# CC3200 register map
Vendor: Texas Instruments; Series: SimpleLink; File version: 1.0
CPU: CM4 r0p1, little endian, MPU, no FPU, 3 interrupt priority bits
Registers are 32-bit, read-write, reset 0x0 unless marked. A register's access mark holds for its fields unless they carry their own. Offsets are from the block's base; [hi:lo] are bit positions; {n}, {i} and the like mark numbered series; 'fields as' and 'values as' point back to an identical list.

## TIMER — TIMERA0
Base 0x40030000
0x00 CFG — TIMER_CFG
  [2:0] M
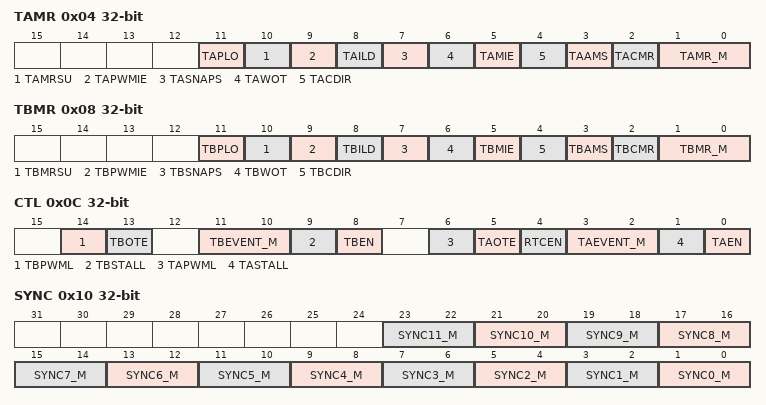
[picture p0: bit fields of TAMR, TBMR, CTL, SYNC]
0x04 TAMR — TIMER_TAMR
  [11] TAPLO — TIMER_TAMR
  [10] TAMRSU — TIMER_TAMR
  [9] TAPWMIE — TIMER_TAMR
  [8] TAILD — TIMER_TAMR
  [7] TASNAPS — TIMER_TAMR
  [6] TAWOT — TIMER_TAMR
  [5] TAMIE — TIMER_TAMR
  [4] TACDIR — TIMER_TAMR
  [3] TAAMS — TIMER_TAMR
  [2] TACMR — TIMER_TAMR
  [1:0] TAMR_M — TIMER_TAMR
0x08 TBMR — TIMER_TBMR
  [11] TBPLO — TIMER_TBMR
  [10] TBMRSU — TIMER_TBMR
  [9] TBPWMIE — TIMER_TBMR
  [8] TBILD — TIMER_TBMR
  [7] TBSNAPS — TIMER_TBMR
  [6] TBWOT — TIMER_TBMR
  [5] TBMIE — TIMER_TBMR
  [4] TBCDIR — TIMER_TBMR
  [3] TBAMS — TIMER_TBMR
  [2] TBCMR — TIMER_TBMR
  [1:0] TBMR_M — TIMER_TBMR
0x0C CTL — TIMER_CTL
  [14] TBPWML — TIMER_CTL
  [13] TBOTE — TIMER_CTL
  [11:10] TBEVENT_M — TIMER_CTL
  [9] TBSTALL — TIMER_CTL
  [8] TBEN — TIMER_CTL
  [6] TAPWML — TIMER_CTL
  [5] TAOTE — TIMER_CTL
  [4] RTCEN — TIMER_CTL
  [3:2] TAEVENT_M — TIMER_CTL
  [1] TASTALL — TIMER_CTL
  [0] TAEN — TIMER_CTL
0x10 SYNC — TIMER_SYNC
  [2n+1:2n] SYNC{n}_M (n=0..11) — TIMER_SYNC
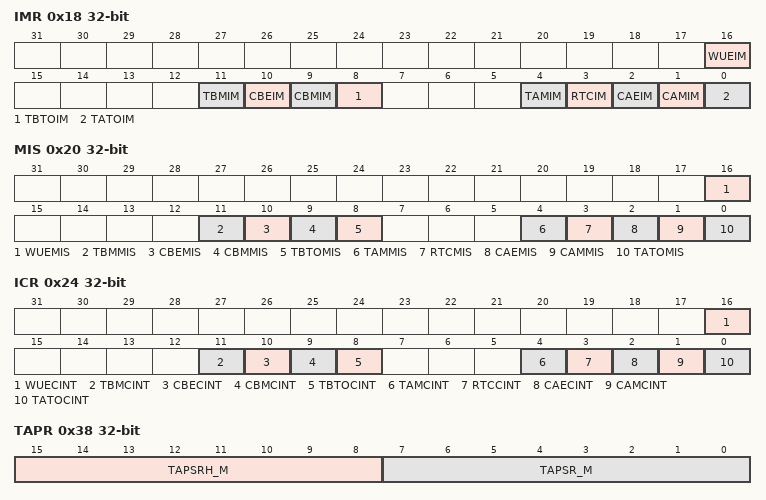
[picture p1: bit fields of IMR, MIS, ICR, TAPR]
0x18 IMR — TIMER_IMR
  [16] WUEIM — TIMER_IMR
  [11] TBMIM — TIMER_IMR
  [10] CBEIM — TIMER_IMR
  [9] CBMIM — TIMER_IMR
  [8] TBTOIM — TIMER_IMR
  [4] TAMIM — TIMER_IMR
  [3] RTCIM — TIMER_IMR
  [2] CAEIM — TIMER_IMR
  [1] CAMIM — TIMER_IMR
  [0] TATOIM — TIMER_IMR
0x1C RIS — TIMER_RIS
  [16] WUERIS — TIMER_RIS
  [11] TBMRIS — TIMER_RIS
  [10] CBEMIS — TIMER_RIS
  [10] CBERIS — TIMER_RIS
  [9] CBMMIS — TIMER_RIS
  [9] CBMRIS — TIMER_RIS
  [8] TBTOMIS — TIMER_RIS
  [8] TBTORIS — TIMER_RIS
  [4] TAMRIS — TIMER_RIS
  [3] RTCMIS — TIMER_RIS
  [3] RTCRIS — TIMER_RIS
  [2] CAEMIS — TIMER_RIS
  [2] CAERIS — TIMER_RIS
  [1] CAMMIS — TIMER_RIS
  [1] CAMRIS — TIMER_RIS
  [0] TATOMIS — TIMER_RIS
  [0] TATORIS — TIMER_RIS
0x20 MIS — TIMER_MIS
  [16] WUEMIS — TIMER_MIS
  [11] TBMMIS — TIMER_MIS
  [10] CBEMIS — TIMER_MIS
  [9] CBMMIS — TIMER_MIS
  [8] TBTOMIS — TIMER_MIS
  [4] TAMMIS — TIMER_MIS
  [3] RTCMIS — TIMER_MIS
  [2] CAEMIS — TIMER_MIS
  [1] CAMMIS — TIMER_MIS
  [0] TATOMIS — TIMER_MIS
0x24 ICR — TIMER_ICR
  [16] WUECINT — TIMER_ICR
  [11] TBMCINT — TIMER_ICR
  [10] CBECINT — TIMER_ICR
  [9] CBMCINT — TIMER_ICR
  [8] TBTOCINT — TIMER_ICR
  [4] TAMCINT — TIMER_ICR
  [3] RTCCINT — TIMER_ICR
  [2] CAECINT — TIMER_ICR
  [1] CAMCINT — TIMER_ICR
  [0] TATOCINT — TIMER_ICR
0x28 TAILR — TIMER_TAILR
  [31:0] M
0x2C TBILR — TIMER_TBILR
  [31:0] M
0x30 TAMATCHR — TIMER_TAMATCHR
  [31:16] TAMRH — TIMER_TAMATCHR
  [31:16] TAMRH_M — TIMER_TAMATCHR
  [31:0] TAMR_M — TIMER_TAMATCHR
  [15:0] TAMRL — TIMER_TAMATCHR
  [15:0] TAMRL_M — TIMER_TAMATCHR
0x34 TBMATCHR — TIMER_TBMATCHR
  [31:0] TBMR_M — TIMER_TBMATCHR
  [15:0] TBMRL — TIMER_TBMATCHR
  [15:0] TBMRL_M — TIMER_TBMATCHR
0x38 TAPR — TIMER_TAPR
  [15:8] TAPSRH_M — TIMER_TAPR
  [7:0] TAPSR_M — TIMER_TAPR
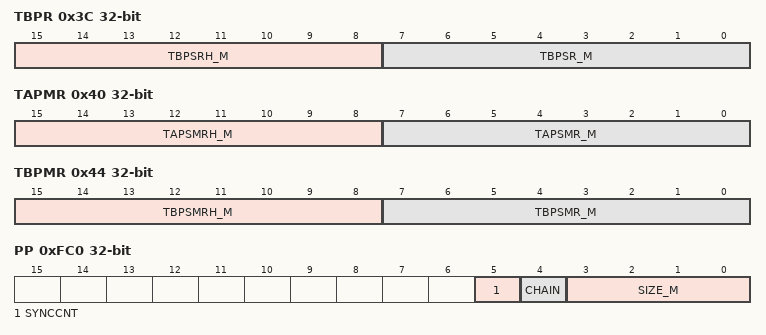
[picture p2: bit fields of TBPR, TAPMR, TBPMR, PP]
0x3C TBPR — TIMER_TBPR
  [15:8] TBPSRH_M — TIMER_TBPR
  [7:0] TBPSR_M — TIMER_TBPR
0x40 TAPMR — TIMER_TAPMR
  [15:8] TAPSMRH_M — TIMER_TAPMR
  [7:0] TAPSMR_M — TIMER_TAPMR
0x44 TBPMR — TIMER_TBPMR
  [15:8] TBPSMRH_M — TIMER_TBPMR
  [7:0] TBPSMR_M — TIMER_TBPMR
0x48 TAR — TIMER_TAR
  [31:0] M
0x4C TBR — TIMER_TBR
  [31:0] M
0x50 TAV — TIMER_TAV
  [31:0] M
0x54 TBV — TIMER_TBV
  [31:0] M
0x58 RTCPD — TIMER_RTCPD
  [15:0] RTCPD_M
0x5C TAPS — TIMER_TAPS
  [15:0] PSS_M
0x60 TBPS — TIMER_TBPS
  [15:0] PSS_M
0x64 TAPV — TIMER_TAPV
  [15:0] PSV_M
0x68 TBPV — TIMER_TBPV
  [15:0] PSV_M
0x6C DMAEV — TIMER_DMAEV
0xFC0 PP — TIMER_PP
  [5] SYNCCNT — TIMER_PP
  [4] CHAIN — TIMER_PP
  [3:0] SIZE_M — TIMER_PP

## TIMER — TIMERA1
Base 0x40031000
0x00 CFG — TIMER_CFG
  [2:0] M
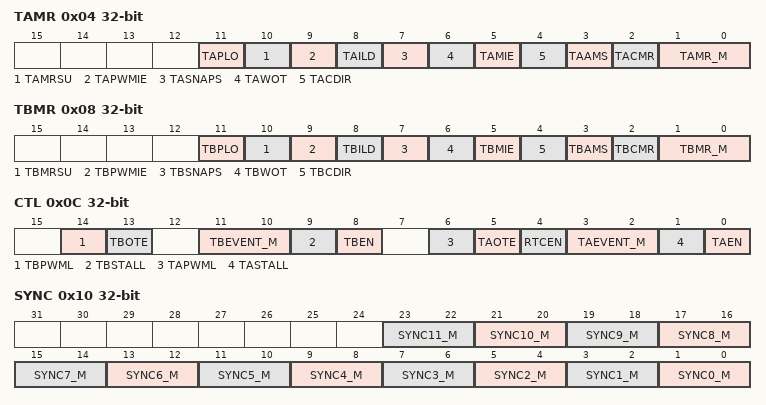
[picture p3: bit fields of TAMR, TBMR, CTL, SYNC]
0x04 TAMR — TIMER_TAMR
  fields as TAMR
0x08 TBMR — TIMER_TBMR
  fields as TBMR
0x0C CTL — TIMER_CTL
  fields as CTL
0x10 SYNC — TIMER_SYNC
  [2n+1:2n] SYNC{n}_M (n=0..11) — TIMER_SYNC
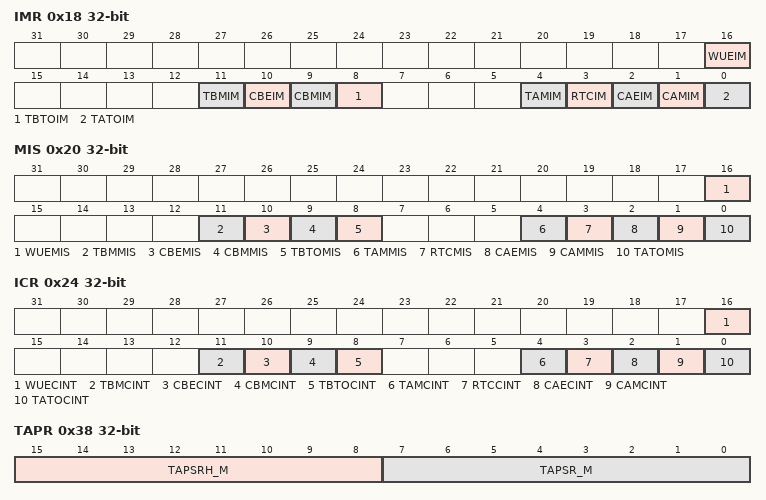
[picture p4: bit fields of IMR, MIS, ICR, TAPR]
0x18 IMR — TIMER_IMR
  fields as IMR
0x1C RIS — TIMER_RIS
  fields as RIS
0x20 MIS — TIMER_MIS
  fields as MIS
0x24 ICR — TIMER_ICR
  fields as ICR
0x28 TAILR — TIMER_TAILR
  [31:0] M
0x2C TBILR — TIMER_TBILR
  [31:0] M
0x30 TAMATCHR — TIMER_TAMATCHR
  fields as TAMATCHR
0x34 TBMATCHR — TIMER_TBMATCHR
  fields as TBMATCHR
0x38 TAPR — TIMER_TAPR
  [15:8] TAPSRH_M — TIMER_TAPR
  [7:0] TAPSR_M — TIMER_TAPR
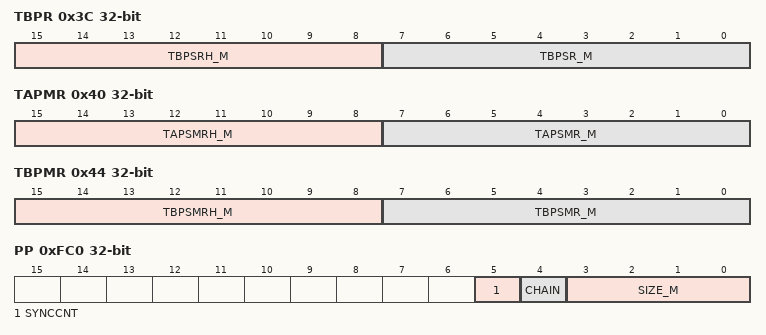
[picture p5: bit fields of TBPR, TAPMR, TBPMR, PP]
0x3C TBPR — TIMER_TBPR
  [15:8] TBPSRH_M — TIMER_TBPR
  [7:0] TBPSR_M — TIMER_TBPR
0x40 TAPMR — TIMER_TAPMR
  [15:8] TAPSMRH_M — TIMER_TAPMR
  [7:0] TAPSMR_M — TIMER_TAPMR
0x44 TBPMR — TIMER_TBPMR
  [15:8] TBPSMRH_M — TIMER_TBPMR
  [7:0] TBPSMR_M — TIMER_TBPMR
0x48 TAR — TIMER_TAR
  [31:0] M
0x4C TBR — TIMER_TBR
  [31:0] M
0x50 TAV — TIMER_TAV
  [31:0] M
0x54 TBV — TIMER_TBV
  [31:0] M
0x58 RTCPD — TIMER_RTCPD
  [15:0] RTCPD_M
0x5C TAPS — TIMER_TAPS
  [15:0] PSS_M
0x60 TBPS — TIMER_TBPS
  [15:0] PSS_M
0x64 TAPV — TIMER_TAPV
  [15:0] PSV_M
0x68 TBPV — TIMER_TBPV
  [15:0] PSV_M
0x6C DMAEV — TIMER_DMAEV
0xFC0 PP — TIMER_PP
  fields as PP

## TIMER — TIMERA2
Base 0x40032000
0x00 CFG — TIMER_CFG
  [2:0] M
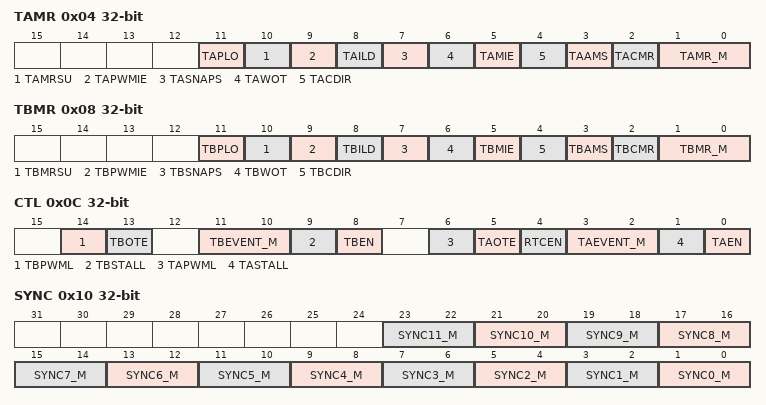
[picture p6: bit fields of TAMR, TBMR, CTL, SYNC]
0x04 TAMR — TIMER_TAMR
  fields as TAMR
0x08 TBMR — TIMER_TBMR
  fields as TBMR
0x0C CTL — TIMER_CTL
  fields as CTL
0x10 SYNC — TIMER_SYNC
  [2n+1:2n] SYNC{n}_M (n=0..11) — TIMER_SYNC
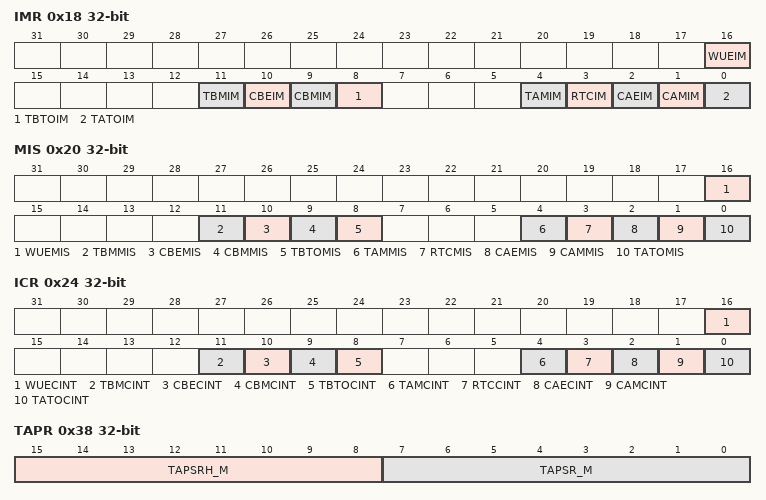
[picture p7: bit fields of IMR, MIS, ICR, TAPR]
0x18 IMR — TIMER_IMR
  fields as IMR
0x1C RIS — TIMER_RIS
  fields as RIS
0x20 MIS — TIMER_MIS
  fields as MIS
0x24 ICR — TIMER_ICR
  fields as ICR
0x28 TAILR — TIMER_TAILR
  [31:0] M
0x2C TBILR — TIMER_TBILR
  [31:0] M
0x30 TAMATCHR — TIMER_TAMATCHR
  fields as TAMATCHR
0x34 TBMATCHR — TIMER_TBMATCHR
  fields as TBMATCHR
0x38 TAPR — TIMER_TAPR
  [15:8] TAPSRH_M — TIMER_TAPR
  [7:0] TAPSR_M — TIMER_TAPR
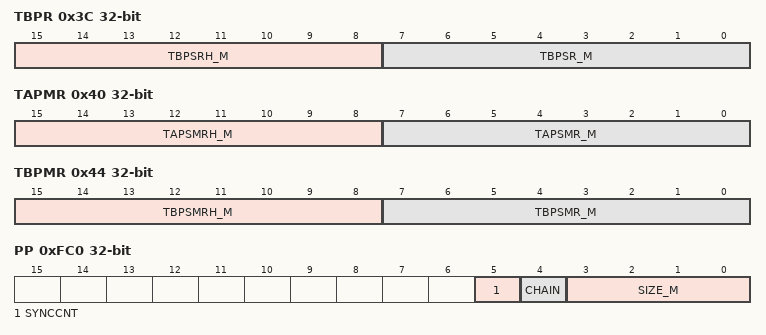
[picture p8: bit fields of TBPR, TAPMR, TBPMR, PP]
0x3C TBPR — TIMER_TBPR
  [15:8] TBPSRH_M — TIMER_TBPR
  [7:0] TBPSR_M — TIMER_TBPR
0x40 TAPMR — TIMER_TAPMR
  [15:8] TAPSMRH_M — TIMER_TAPMR
  [7:0] TAPSMR_M — TIMER_TAPMR
0x44 TBPMR — TIMER_TBPMR
  [15:8] TBPSMRH_M — TIMER_TBPMR
  [7:0] TBPSMR_M — TIMER_TBPMR
0x48 TAR — TIMER_TAR
  [31:0] M
0x4C TBR — TIMER_TBR
  [31:0] M
0x50 TAV — TIMER_TAV
  [31:0] M
0x54 TBV — TIMER_TBV
  [31:0] M
0x58 RTCPD — TIMER_RTCPD
  [15:0] RTCPD_M
0x5C TAPS — TIMER_TAPS
  [15:0] PSS_M
0x60 TBPS — TIMER_TBPS
  [15:0] PSS_M
0x64 TAPV — TIMER_TAPV
  [15:0] PSV_M
0x68 TBPV — TIMER_TBPV
  [15:0] PSV_M
0x6C DMAEV — TIMER_DMAEV
0xFC0 PP — TIMER_PP
  fields as PP

## TIMER — TIMERA3
Base 0x40033000
0x00 CFG — TIMER_CFG
  [2:0] M
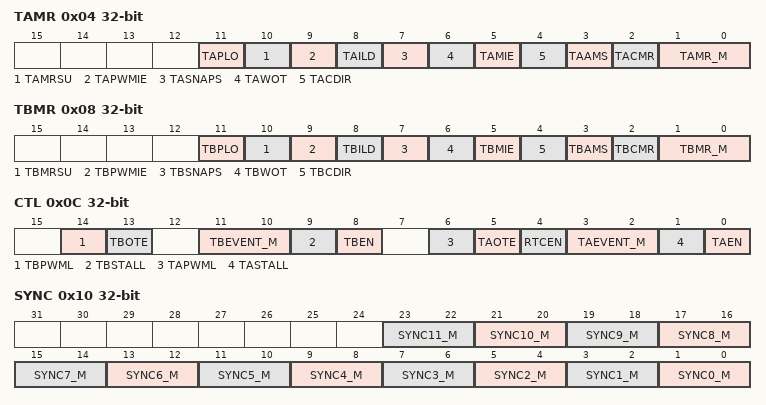
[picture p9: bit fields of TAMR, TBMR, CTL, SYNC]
0x04 TAMR — TIMER_TAMR
  fields as TAMR
0x08 TBMR — TIMER_TBMR
  fields as TBMR
0x0C CTL — TIMER_CTL
  fields as CTL
0x10 SYNC — TIMER_SYNC
  [2n+1:2n] SYNC{n}_M (n=0..11) — TIMER_SYNC
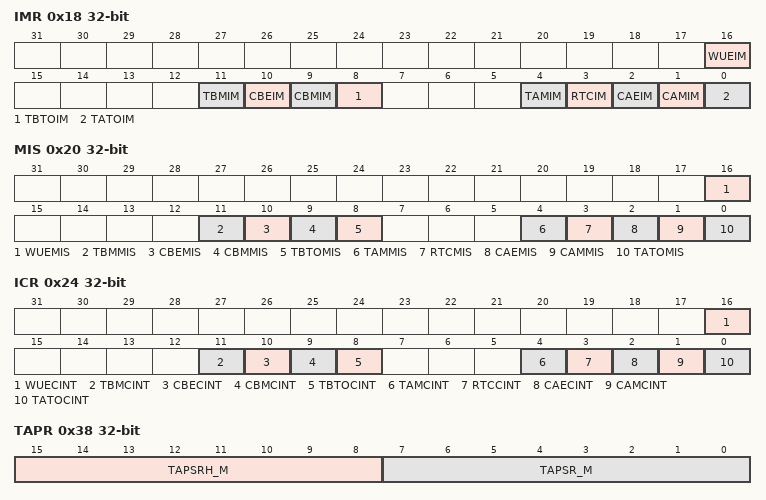
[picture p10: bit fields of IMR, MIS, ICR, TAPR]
0x18 IMR — TIMER_IMR
  fields as IMR
0x1C RIS — TIMER_RIS
  fields as RIS
0x20 MIS — TIMER_MIS
  fields as MIS
0x24 ICR — TIMER_ICR
  fields as ICR
0x28 TAILR — TIMER_TAILR
  [31:0] M
0x2C TBILR — TIMER_TBILR
  [31:0] M
0x30 TAMATCHR — TIMER_TAMATCHR
  fields as TAMATCHR
0x34 TBMATCHR — TIMER_TBMATCHR
  fields as TBMATCHR
0x38 TAPR — TIMER_TAPR
  [15:8] TAPSRH_M — TIMER_TAPR
  [7:0] TAPSR_M — TIMER_TAPR
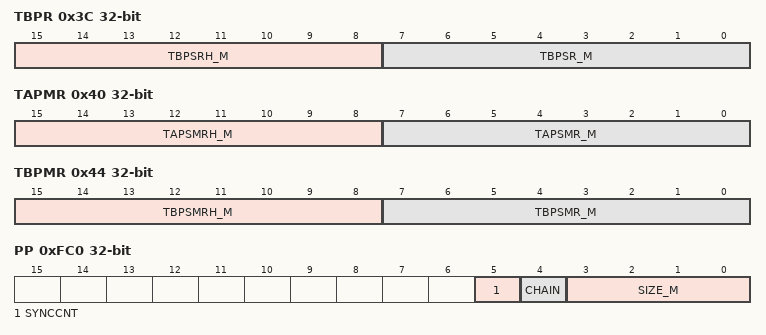
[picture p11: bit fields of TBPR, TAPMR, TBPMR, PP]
0x3C TBPR — TIMER_TBPR
  [15:8] TBPSRH_M — TIMER_TBPR
  [7:0] TBPSR_M — TIMER_TBPR
0x40 TAPMR — TIMER_TAPMR
  [15:8] TAPSMRH_M — TIMER_TAPMR
  [7:0] TAPSMR_M — TIMER_TAPMR
0x44 TBPMR — TIMER_TBPMR
  [15:8] TBPSMRH_M — TIMER_TBPMR
  [7:0] TBPSMR_M — TIMER_TBPMR
0x48 TAR — TIMER_TAR
  [31:0] M
0x4C TBR — TIMER_TBR
  [31:0] M
0x50 TAV — TIMER_TAV
  [31:0] M
0x54 TBV — TIMER_TBV
  [31:0] M
0x58 RTCPD — TIMER_RTCPD
  [15:0] RTCPD_M
0x5C TAPS — TIMER_TAPS
  [15:0] PSS_M
0x60 TBPS — TIMER_TBPS
  [15:0] PSS_M
0x64 TAPV — TIMER_TAPV
  [15:0] PSV_M
0x68 TBPV — TIMER_TBPV
  [15:0] PSV_M
0x6C DMAEV — TIMER_DMAEV
0xFC0 PP — TIMER_PP
  fields as PP
